VERSION ""

NS_ :

BS_:

BU_: Drehmomentkoordination Elektromotorsteuerung Getriebesteuerung Ladesteuerung Motorsteuerung System

BO_ 637 Elektromotorsteuerung_Elektromot: 2 Elektromotorsteuerung
 SG_ ElektromotorDrehmomentIst : 0|15@1- (0.1,0.0) [-1000.0|1000.0] "Nm"  Drehmomentkoordination,Getriebesteuerung,Motorsteuerung,System

BO_ 638 Drehmomentkoordination_Antrieb_D: 2 Drehmomentkoordination
 SG_ AntriebDrehmomentSoll : 0|16@1- (0.1,0.0) [-1000.0|2000.0] "Nm"  Elektromotorsteuerung,Getriebesteuerung,Motorsteuerung,System

BO_ 636 Getriebesteuerung_Getriebe_Ueber: 2 Getriebesteuerung
 SG_ GetriebeUebersetzungIst : 0|11@1+ (0.01,0.0) [0.0|20.0] "ratio"  Drehmomentkoordination,Elektromotorsteuerung,Motorsteuerung,System

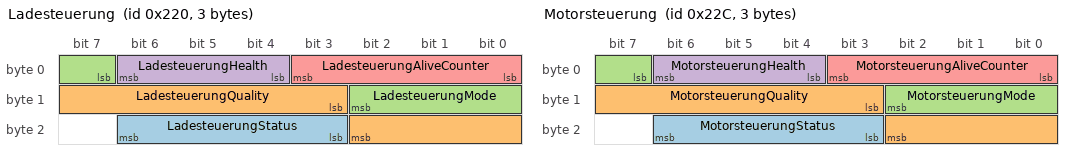
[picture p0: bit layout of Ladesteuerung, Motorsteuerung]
BO_ 544 Ladesteuerung: 3 Ladesteuerung
 SG_ LadesteuerungStatus : 19|4@1+ (1,0) [0.0|15.0] "code"  System
 SG_ LadesteuerungQuality : 11|8@1+ (0.5,0.0) [0.0|100.0] "%"  System
 SG_ LadesteuerungMode : 7|4@1+ (1,0) [0.0|15.0] "code"  System
 SG_ LadesteuerungHealth : 4|3@1+ (1,0) [0.0|7.0] "code"  System
 SG_ LadesteuerungAliveCounter : 0|4@1+ (1,0) [0.0|15.0] "count"  System

BO_ 556 Motorsteuerung: 3 Motorsteuerung
 SG_ MotorsteuerungStatus : 19|4@1+ (1,0) [0.0|15.0] "code"  System
 SG_ MotorsteuerungQuality : 11|8@1+ (0.5,0.0) [0.0|100.0] "%"  System
 SG_ MotorsteuerungMode : 7|4@1+ (1,0) [0.0|15.0] "code"  System
 SG_ MotorsteuerungHealth : 4|3@1+ (1,0) [0.0|7.0] "code"  System
 SG_ MotorsteuerungAliveCounter : 0|4@1+ (1,0) [0.0|15.0] "count"  System

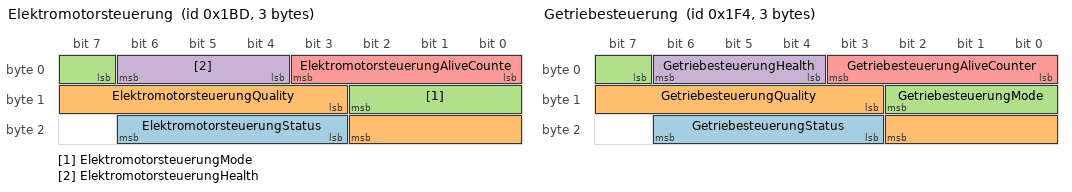
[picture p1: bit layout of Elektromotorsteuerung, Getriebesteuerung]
BO_ 445 Elektromotorsteuerung: 3 Elektromotorsteuerung
 SG_ ElektromotorsteuerungStatus : 19|4@1+ (1,0) [0.0|15.0] "code"  System
 SG_ ElektromotorsteuerungQuality : 11|8@1+ (0.5,0.0) [0.0|100.0] "%"  System
 SG_ ElektromotorsteuerungMode : 7|4@1+ (1,0) [0.0|15.0] "code"  System
 SG_ ElektromotorsteuerungHealth : 4|3@1+ (1,0) [0.0|7.0] "code"  System
 SG_ ElektromotorsteuerungAliveCounte : 0|4@1+ (1,0) [0.0|15.0] "count"  System

BO_ 635 Motorsteuerung_Motor_Drehmoment_: 2 Motorsteuerung
 SG_ MotorDrehmomentIst : 0|15@1- (0.1,0.0) [-500.0|1000.0] "Nm"  Drehmomentkoordination,Elektromotorsteuerung,Getriebesteuerung,System

BO_ 500 Getriebesteuerung: 3 Getriebesteuerung
 SG_ GetriebesteuerungStatus : 19|4@1+ (1,0) [0.0|15.0] "code"  System
 SG_ GetriebesteuerungQuality : 11|8@1+ (0.5,0.0) [0.0|100.0] "%"  System
 SG_ GetriebesteuerungMode : 7|4@1+ (1,0) [0.0|15.0] "code"  System
 SG_ GetriebesteuerungHealth : 4|3@1+ (1,0) [0.0|7.0] "code"  System
 SG_ GetriebesteuerungAliveCounter : 0|4@1+ (1,0) [0.0|15.0] "count"  System

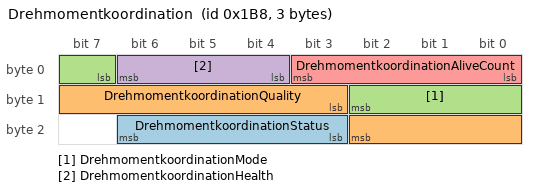
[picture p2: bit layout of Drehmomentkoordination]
BO_ 440 Drehmomentkoordination: 3 Drehmomentkoordination
 SG_ DrehmomentkoordinationStatus : 19|4@1+ (1,0) [0.0|15.0] "code"  System
 SG_ DrehmomentkoordinationQuality : 11|8@1+ (0.5,0.0) [0.0|100.0] "%"  System
 SG_ DrehmomentkoordinationMode : 7|4@1+ (1,0) [0.0|15.0] "code"  System
 SG_ DrehmomentkoordinationHealth : 4|3@1+ (1,0) [0.0|7.0] "code"  System
 SG_ DrehmomentkoordinationAliveCount : 0|4@1+ (1,0) [0.0|15.0] "count"  System

CM_ BO_ 637 "CanonicalMessage=40cd363e-15df-488c-a8ba-be4f4dd809da; Network=Antriebsstrang_01-S01-CAP-S01; Technology=can_fd";
CM_ SG_ 637 ElektromotorDrehmomentIst "CanonicalSignal=7cc37c48-c753-4976-a82b-4743156ada56";
CM_ BO_ 638 "CanonicalMessage=27f5731e-36ee-466b-9bb5-20676227f02a; Network=Antriebsstrang_01-S01-CAP-S01; Technology=can_fd";
CM_ SG_ 638 AntriebDrehmomentSoll "CanonicalSignal=c56ca419-8b42-4f25-a7e8-c243a3e9e5ed";
CM_ BO_ 636 "CanonicalMessage=9e268618-25c2-4547-b32d-4086ed98b714; Network=Antriebsstrang_01-S01-CAP-S01; Technology=can_fd";
CM_ SG_ 636 GetriebeUebersetzungIst "CanonicalSignal=b788bbfb-04a1-4968-a0a2-bc4bf81efc88";
CM_ BO_ 544 "CanonicalMessage=c42a221d-94a2-4d18-ba2e-f275623c156e; Network=Antriebsstrang_01-S01-CAP-S01; Technology=can_fd";
CM_ SG_ 544 LadesteuerungStatus "CanonicalSignal=bbfe6d9d-f748-4c68-8475-8d37d81a2cff";
CM_ SG_ 544 LadesteuerungQuality "CanonicalSignal=af8e4a77-f090-478d-8c09-cb959768c85b";
CM_ SG_ 544 LadesteuerungMode "CanonicalSignal=3a3766c5-5251-4309-8ea5-334fc35088f0";
CM_ SG_ 544 LadesteuerungHealth "CanonicalSignal=bef95f05-1317-480f-a83e-79b77417a362";
CM_ SG_ 544 LadesteuerungAliveCounter "CanonicalSignal=200c9b80-471e-49d7-90f2-2ce5f2ee802e";
CM_ BO_ 556 "CanonicalMessage=01d3429a-68ee-4300-a8bf-33939a68f2cf; Network=Antriebsstrang_01-S01-CAP-S01; Technology=can_fd";
CM_ SG_ 556 MotorsteuerungStatus "CanonicalSignal=9422ec71-ba8d-40f7-99f1-6f23d39fedeb";
CM_ SG_ 556 MotorsteuerungQuality "CanonicalSignal=b9a478be-482c-4cd2-8d90-817ab11ae2c0";
CM_ SG_ 556 MotorsteuerungMode "CanonicalSignal=51d1996b-ca50-4084-8a4b-2e99c1dbd8c8";
CM_ SG_ 556 MotorsteuerungHealth "CanonicalSignal=e1023df4-f92f-4378-a937-87d6d36857cd";
CM_ SG_ 556 MotorsteuerungAliveCounter "CanonicalSignal=fbf7d14a-9096-4151-9d4f-c039c2b1e1ba";
CM_ BO_ 445 "CanonicalMessage=daca8ff6-713b-47fb-b33a-181771a0c05f; Network=Antriebsstrang_01-S01-CAP-S01; Technology=can_fd";
CM_ SG_ 445 ElektromotorsteuerungStatus "CanonicalSignal=097f2755-8646-41a3-883c-5c5e88665057";
CM_ SG_ 445 ElektromotorsteuerungQuality "CanonicalSignal=88e72a2f-bc37-405c-ba0e-712fae6c506e";
CM_ SG_ 445 ElektromotorsteuerungMode "CanonicalSignal=7b927925-c4d7-46fe-8ecc-00216d3c3a87";
CM_ SG_ 445 ElektromotorsteuerungHealth "CanonicalSignal=2731f8f3-9e2e-4ee7-a052-b467b0b7b20c";
CM_ SG_ 445 ElektromotorsteuerungAliveCounte "CanonicalSignal=5ab0c3de-c979-4b13-ae24-00f5c1450459";
CM_ BO_ 635 "CanonicalMessage=d50c1f2e-a2e2-4f82-8c0e-2b240ab310a8; Network=Antriebsstrang_01-S01-CAP-S01; Technology=can_fd";
CM_ SG_ 635 MotorDrehmomentIst "CanonicalSignal=ae050fbd-52c7-4f49-b642-243bb938a377";
CM_ BO_ 500 "CanonicalMessage=1cbf1d6a-bbe8-4e9d-8972-ec92e3bbc710; Network=Antriebsstrang_01-S01-CAP-S01; Technology=can_fd";
CM_ SG_ 500 GetriebesteuerungStatus "CanonicalSignal=d3f7fe5e-2e65-4240-9c94-351339b3146b";
CM_ SG_ 500 GetriebesteuerungQuality "CanonicalSignal=b99baf66-d526-4282-89b6-e52a971b883c";
CM_ SG_ 500 GetriebesteuerungMode "CanonicalSignal=932c1661-54a9-4194-bb55-6f5619d5786c";
CM_ SG_ 500 GetriebesteuerungHealth "CanonicalSignal=277259f0-0311-4724-800d-a6be465a68b7";
CM_ SG_ 500 GetriebesteuerungAliveCounter "CanonicalSignal=b6832165-35cb-4749-a6e9-865447192e47";
CM_ BO_ 440 "CanonicalMessage=af84f50e-5360-4de7-9805-de7cfd827030; Network=Antriebsstrang_01-S01-CAP-S01; Technology=can_fd";
CM_ SG_ 440 DrehmomentkoordinationStatus "CanonicalSignal=e7b8b7db-b2f4-4f49-a409-6c582824f903";
CM_ SG_ 440 DrehmomentkoordinationQuality "CanonicalSignal=4eff1dc3-454a-492a-bc16-c08f66b64b37";
CM_ SG_ 440 DrehmomentkoordinationMode "CanonicalSignal=b2be84aa-8bc1-4c49-86b0-41cd190380a7";
CM_ SG_ 440 DrehmomentkoordinationHealth "CanonicalSignal=a2a97595-e90a-4192-aedf-c1aa358bdd4d";
CM_ SG_ 440 DrehmomentkoordinationAliveCount "CanonicalSignal=8d521d95-1cb7-4cef-9b89-055aa04387b9";
BA_DEF_ BO_  "VFrameFormat" ENUM  "StandardCAN","ExtendedCAN","StandardCAN_FD","ExtendedCAN_FD";
BA_DEF_DEF_  "VFrameFormat" "0";
BA_ "VFrameFormat" BO_ 637 2;
BA_ "VFrameFormat" BO_ 638 2;
BA_ "VFrameFormat" BO_ 636 2;
BA_ "VFrameFormat" BO_ 544 2;
BA_ "VFrameFormat" BO_ 556 2;
BA_ "VFrameFormat" BO_ 445 2;
BA_ "VFrameFormat" BO_ 635 2;
BA_ "VFrameFormat" BO_ 500 2;
BA_ "VFrameFormat" BO_ 440 2;
